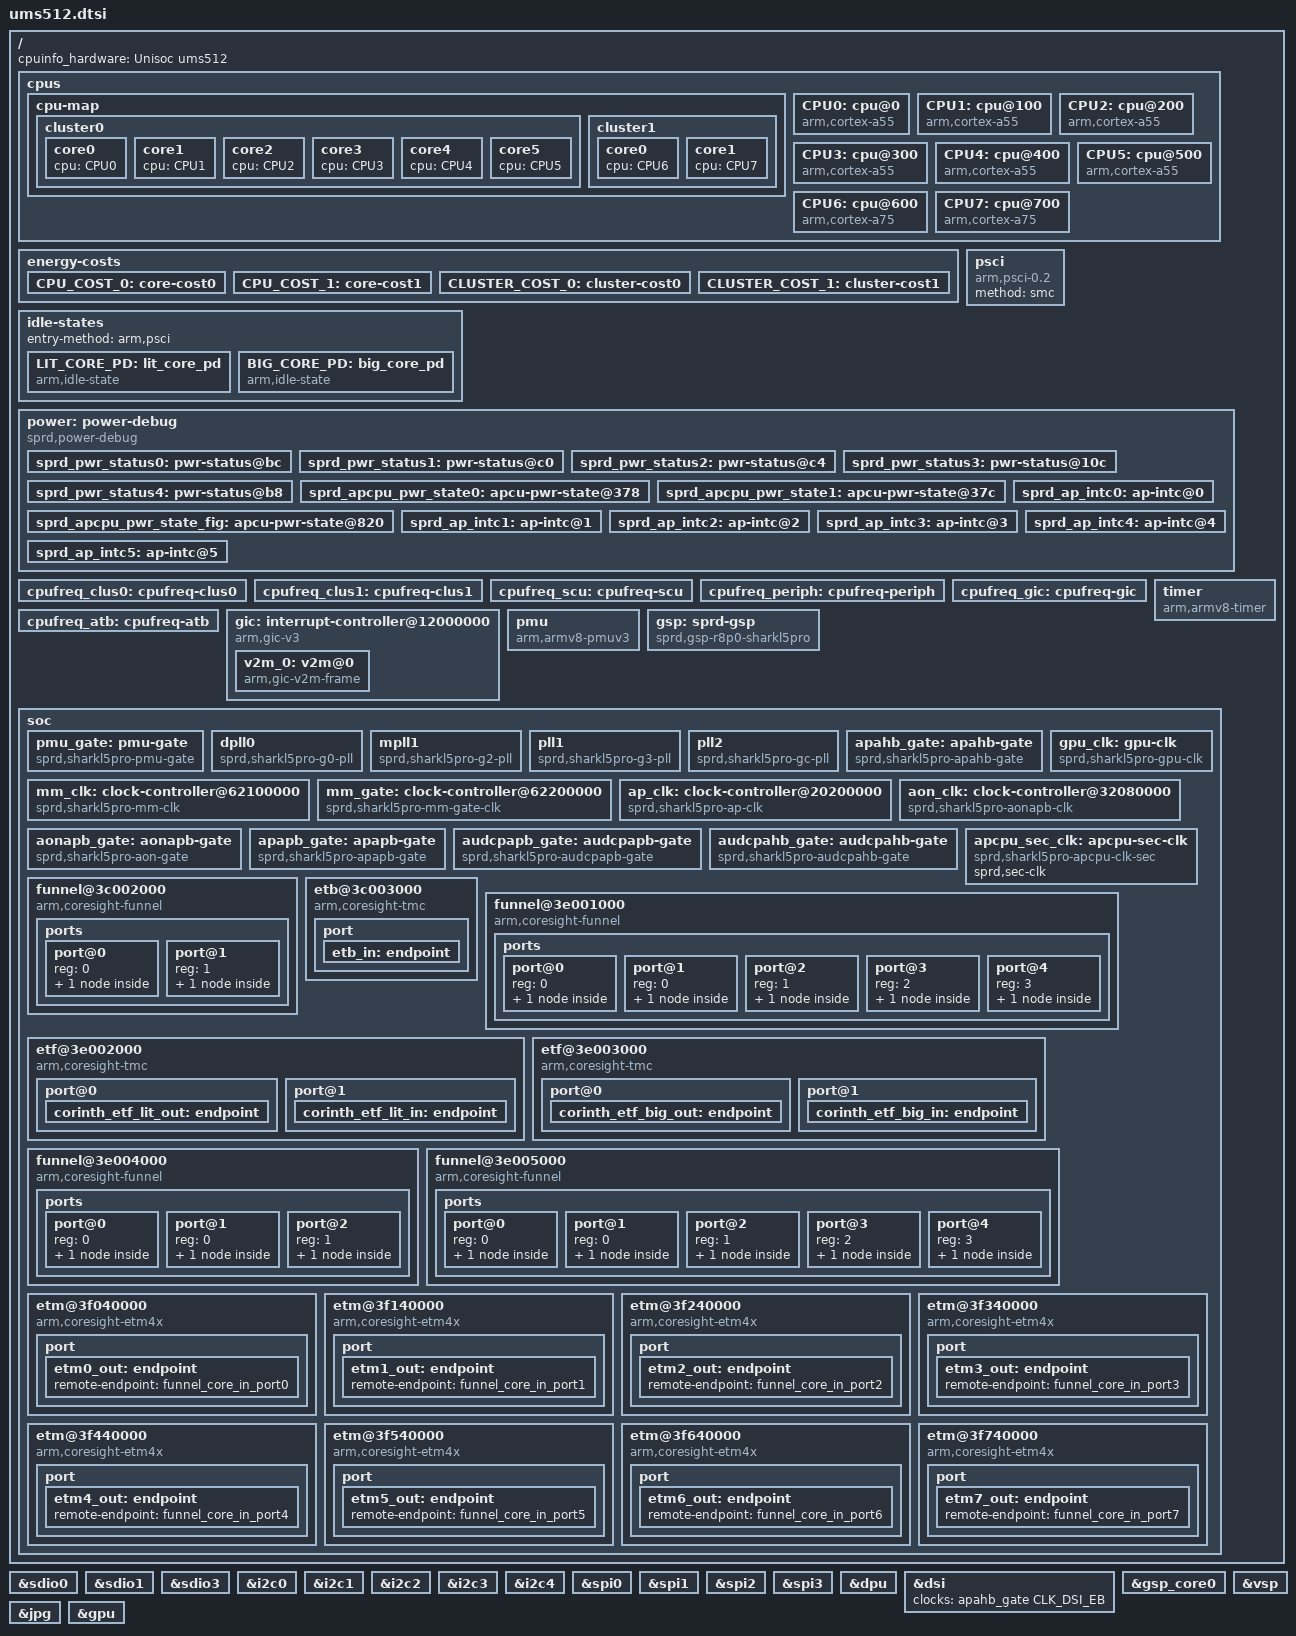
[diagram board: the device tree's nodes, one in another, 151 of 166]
// SPDX-License-Identifier: (GPL-2.0+ OR MIT)
/*
 * Unisoc Sharkl5Pro platform DTS file
 *
 * Copyright (C) 2018, Unisoc Communications Inc.
 */

#include "sharkl5Pro.dtsi"
#include "ums512-qos.dtsi"

/ {
	cpuinfo_hardware = "Unisoc ums512";

	cpus {
		#address-cells = <2>;
		#size-cells = <0>;

		cpu-map {
			cluster0 {
				core0 {
					cpu = <&CPU0>;
				};
				core1 {
					cpu = <&CPU1>;
				};
				core2 {
					cpu = <&CPU2>;
				};
				core3 {
					cpu = <&CPU3>;
				};
				core4 {
					cpu = <&CPU4>;
				};
				core5 {
					cpu = <&CPU5>;
				};
			};
			cluster1 {
				core0 {
					cpu = <&CPU6>;
				};
				core1 {
					cpu = <&CPU7>;
				};
			};
		};

		CPU0: cpu@0 {
			device_type = "cpu";
			compatible = "arm,cortex-a55","arm,armv8";
			reg = <0x0 0x0>;
			enable-method = "psci";
			cpu-idle-states = <&LIT_CORE_PD>;
			cpufreq-data-v1 = <&cpufreq_clus0>;
			sched-energy-costs = <&CPU_COST_0 &CLUSTER_COST_0>;
			capacity-dmips-mhz = <544>;
			sugov_slack_timer;
		};
		CPU1: cpu@100 {
			device_type = "cpu";
			compatible = "arm,cortex-a55","arm,armv8";
			reg = <0x0 0x100>;
			enable-method = "psci";
			cpu-idle-states = <&LIT_CORE_PD>;
			sched-energy-costs = <&CPU_COST_0 &CLUSTER_COST_0>;
			capacity-dmips-mhz = <544>;
			cpufreq-data-v1 = <&cpufreq_clus0>;
		};
		CPU2: cpu@200 {
			device_type = "cpu";
			compatible = "arm,cortex-a55","arm,armv8";
			reg = <0x0 0x200>;
			enable-method = "psci";
			cpu-idle-states = <&LIT_CORE_PD>;
			sched-energy-costs = <&CPU_COST_0 &CLUSTER_COST_0>;
			capacity-dmips-mhz = <544>;
			cpufreq-data-v1 = <&cpufreq_clus0>;
		};
		CPU3: cpu@300 {
			device_type = "cpu";
			compatible = "arm,cortex-a55","arm,armv8";
			reg = <0x0 0x300>;
			enable-method = "psci";
			cpu-idle-states = <&LIT_CORE_PD>;
			sched-energy-costs = <&CPU_COST_0 &CLUSTER_COST_0>;
			capacity-dmips-mhz = <544>;
			cpufreq-data-v1 = <&cpufreq_clus0>;
		};
		CPU4: cpu@400 {
			device_type = "cpu";
			compatible = "arm,cortex-a55","arm,armv8";
			reg = <0x0 0x400>;
			enable-method = "psci";
			cpu-idle-states = <&LIT_CORE_PD>;
			sched-energy-costs = <&CPU_COST_0 &CLUSTER_COST_0>;
			capacity-dmips-mhz = <544>;
			cpufreq-data-v1 = <&cpufreq_clus0>;
		};
		CPU5: cpu@500 {
			device_type = "cpu";
			compatible = "arm,cortex-a55","arm,armv8";
			reg = <0x0 0x500>;
			enable-method = "psci";
			cpu-idle-states = <&LIT_CORE_PD>;
			sched-energy-costs = <&CPU_COST_0 &CLUSTER_COST_0>;
			capacity-dmips-mhz = <544>;
			cpufreq-data-v1 = <&cpufreq_clus0>;
		};
		CPU6: cpu@600 {
			device_type = "cpu";
			compatible = "arm,cortex-a75","arm,armv8";
			reg = <0x0 0x600>;
			enable-method = "psci";
			cpu-idle-states = <&BIG_CORE_PD>;
			sched-energy-costs = <&CPU_COST_1 &CLUSTER_COST_1>;
			capacity-dmips-mhz = <1024>;
			cpufreq-data-v1 = <&cpufreq_clus1>;
		};
		CPU7: cpu@700 {
			device_type = "cpu";
			compatible = "arm,cortex-a75","arm,armv8";
			reg = <0x0 0x700>;
			enable-method = "psci";
			cpu-idle-states = <&BIG_CORE_PD>;
			sched-energy-costs = <&CPU_COST_1 &CLUSTER_COST_1>;
			capacity-dmips-mhz = <1024>;
			cpufreq-data-v1 = <&cpufreq_clus1>;
		};
	};

	energy-costs {
		CPU_COST_0: core-cost0 {
			busy-cost-data = <
				164	30		//614MHz
				206	42		//768MHz
				257	56		//962MHz
				307	70		//1144MHz
				329	85		//1229MHz
				397	115		//1482MHz
				412	134		//1536MHz
				460	166		//1716MHz
				488	194		//1820MHz
			>;
			idle-cost-data = <
				6		/* ACTIVE-IDLE */
				6		/* WFI */
				0		/* CORE_PD */
			>;

			busy-cost-data-lp = <
				183	34		//614MHz
				229	54		//768MHz
				287	67		//962MHz
				342	78		//1144MHz
				367	84		//1229MHz
				443	127		//1482MHz
				459	132		//1536MHz
				513	182		//1716MHz
				544	193		//1820MHz
			>;
			idle-cost-data-lp = <
				5		/* ACTIVE-IDLE */
				5		/* WFI */
				0		/* CORE_PD */
			>;

			busy-cost-data-hp = <
				167	34		//614MHz
				209	54		//768MHz
				261	67		//962MHz
				311	78		//1144MHz
				334	84		//1229MHz
				403	127		//1482MHz
				417	132		//1536MHz
				466	182		//1716MHz
				495	193		//1820MHz
				544	224		//2002MHz
			>;
			idle-cost-data-hp = <
				6		/* ACTIVE-IDLE */
				6		/* WFI */
				0		/* CORE_PD */
			>;
		};
		CPU_COST_1: core-cost1 {
			busy-cost-data = <
				621	331		//1229MHz
				748	454		//1482MHz
				776	540		//1536MHz
				880	683		//1742MHz
				945	820		//1872MHz
				1024	984		//2028MHz
			>;
			idle-cost-data = <
				37		/* ACTIVE-IDLE */
				37		/* WFI */
				0		/* CORE_PD */
			>;

			busy-cost-data-lp = <
				691	360		//1229MHz
				834	491		//1482MHz
				864	644		//1536MHz
				980	902		//1742MHz
				1024	943		//1820MHz
			>;
			idle-cost-data-lp = <
				21		/* ACTIVE-IDLE */
				21		/* WFI */
				0		/* CORE_PD */
			>;

			busy-cost-data-hp = <
				629	360		//1229MHz
				758	491		//1482MHz
				786	644		//1536MHz
				891	902		//1742MHz
				931	943		//1820MHz
				1024	1036		//2002MHz
			>;
			idle-cost-data-hp = <
				21		/* ACTIVE-IDLE */
				21		/* WFI */
				0		/* CORE_PD */
			>;
		};
		CLUSTER_COST_0: cluster-cost0 {
			busy-cost-data = <
				164	1		//614MHz
				206	2		//768MHz
				257	3		//962MHz
				307	4		//1144MHz
				329	5		//1229MHz
				397	6		//1482MHz
				412	7		//1536MHz
				460	8		//1716MHz
				488	9		//1820MHz
			>;
			idle-cost-data = <
				0		/* ACTIVE-IDLE */
				0		/* WFI */
				0		/* CORE_PD */
			>;

			busy-cost-data-lp = <
				183	1		//614MHz
				229	2		//768MHz
				287	3	        //962MHz
				342	4		//1144MHz
				367	5		//1229MHz
				443	6		//1482MHz
				459	7		//1536MHz
				513	8		//1716MHz
				544	9		//1820MHz
			>;
			idle-cost-data-lp = <
				0		/* ACTIVE-IDLE */
				0		/* WFI */
				0		/* CORE_PD */
			>;

			busy-cost-data-hp = <
				167	1		//614MHz
				209	2		//768MHz
				261	3		//962MHz
				311	4		//1144MHz
				334	5		//1229MHz
				403	6		//1482MHz
				417	7		//1536MHz
				466	8		//1716MHz
				495	9		//1820MHz
				544	10		//2002MHz
			>;
			idle-cost-data-hp = <
				0		/* ACTIVE-IDLE */
				0		/* WFI */
				0		/* CORE_PD */
			>;
		};
		CLUSTER_COST_1: cluster-cost1 {
			busy-cost-data = <
				621	13		//1229MHz
				748	17		//1482MHz
				776	21		//1536MHz
				880	25		//1742MHz
				945	30		//1872MHz
				1024	35		//2028MHz
			>;
			idle-cost-data = <
				23		/* ACTIVE-IDLE */
				23		/* WFI */
				23		/* CORE_PD */
			>;

			busy-cost-data-lp = <
				691	10		//1229MHz
				834	22		//1482MHz
				864	32		//1536MHz
				980	44		//1742MHz
				1024	46		//1820MHz
			>;
			idle-cost-data-lp = <
				5		/* ACTIVE-IDLE */
				5		/* WFI */
				5		/* CORE_PD */
			>;

			busy-cost-data-hp = <
				629	10		//1229MHz
				758	22		//1482MHz
				786	32		//1536MHz
				891	40		//1742MHz
				931	44		//1820MHz
				1024	46		//2002MHz
			>;
			idle-cost-data-hp = <
				5		/* ACTIVE-IDLE */
				5		/* WFI */
				5		/* CORE_PD */
			>;
		};
	};

	psci {
		compatible = "arm,psci-0.2";
		method = "smc";
	};

	idle-states {
		entry-method = "arm,psci";
		LIT_CORE_PD: lit_core_pd {
			compatible = "arm,idle-state";
			entry-latency-us = <1000>;
			exit-latency-us = <500>;
			min-residency-us = <2500>;
			local-timer-stop;
			arm,psci-suspend-param = <0x00010000>;
		};

		BIG_CORE_PD: big_core_pd {
			compatible = "arm,idle-state";
			entry-latency-us = <4000>;
			exit-latency-us = <4000>;
			min-residency-us = <10000>;
			local-timer-stop;
			arm,psci-suspend-param = <0x00010000>;
		};
	};

	power: power-debug {
		compatible = "sprd,power-debug";
		#address-cells = <1>;
		#size-cells = <0>;

		sprd,sys-ap-ahb = <&ap_ahb_regs>;

		/* <reg-addr mask expect-value> */
		sprd,ap-ahb-reg-tbl =
			<REG_AP_AHB_RF_AHB_EB
			( MASK_AP_AHB_RF_BUSMON_CLOCK_EB
			| MASK_AP_AHB_RF_CKG_EB
			| MASK_AP_AHB_RF_IPI_EB
			| MASK_AP_AHB_RF_DMA_EB
			| MASK_AP_AHB_RF_DMA_ENABLE
			| MASK_AP_AHB_RF_VDMA_EB
			| MASK_AP_AHB_RF_VSP_EB
			| MASK_AP_AHB_RF_DISPC_EB
			| MASK_AP_AHB_RF_DSI_EB )
			MASK_AP_AHB_RF_CKG_EB>,
			<REG_AP_AHB_RF_AP_SYS_FORCE_SLEEP_CFG
			( MASK_AP_AHB_RF_AXI_LP_CTRL_DISABLE
			| MASK_AP_AHB_RF_PERI_FORCE_OFF )
			( MASK_AP_AHB_RF_AXI_LP_CTRL_DISABLE
			| MASK_AP_AHB_RF_PERI_FORCE_OFF)>,
			<REG_AP_AHB_RF_M0_LPC MASK_AP_AHB_RF_MAIN_M0_LP_EB MASK_AP_AHB_RF_MAIN_M0_LP_EB>,
			<REG_AP_AHB_RF_M1_LPC MASK_AP_AHB_RF_MAIN_M1_LP_EB MASK_AP_AHB_RF_MAIN_M1_LP_EB>,
			<REG_AP_AHB_RF_M2_LPC MASK_AP_AHB_RF_MAIN_M2_LP_EB MASK_AP_AHB_RF_MAIN_M2_LP_EB>,
			<REG_AP_AHB_RF_M3_LPC MASK_AP_AHB_RF_MAIN_M3_LP_EB MASK_AP_AHB_RF_MAIN_M3_LP_EB>,
			<REG_AP_AHB_RF_M4_LPC MASK_AP_AHB_RF_MAIN_M4_LP_EB MASK_AP_AHB_RF_MAIN_M4_LP_EB>,
			<REG_AP_AHB_RF_M5_LPC MASK_AP_AHB_RF_MAIN_M5_LP_EB MASK_AP_AHB_RF_MAIN_M5_LP_EB>,
			<REG_AP_AHB_RF_M6_LPC MASK_AP_AHB_RF_MAIN_M6_LP_EB MASK_AP_AHB_RF_MAIN_M6_LP_EB>,
			<REG_AP_AHB_RF_M7_LPC MASK_AP_AHB_RF_MAIN_M7_LP_EB MASK_AP_AHB_RF_MAIN_M7_LP_EB>,
			<REG_AP_AHB_RF_S0_LPC MASK_AP_AHB_RF_MAIN_S0_LP_EB MASK_AP_AHB_RF_MAIN_S0_LP_EB>,
			<REG_AP_AHB_RF_S1_LPC MASK_AP_AHB_RF_MAIN_S1_LP_EB MASK_AP_AHB_RF_MAIN_S1_LP_EB>,
			<REG_AP_AHB_RF_S2_LPC MASK_AP_AHB_RF_MAIN_S2_LP_EB MASK_AP_AHB_RF_MAIN_S2_LP_EB>,
			<REG_AP_AHB_RF_S3_LPC MASK_AP_AHB_RF_MAIN_S3_LP_EB MASK_AP_AHB_RF_MAIN_S3_LP_EB>,
			<REG_AP_AHB_RF_S4_LPC MASK_AP_AHB_RF_MAIN_S4_LP_EB MASK_AP_AHB_RF_MAIN_S4_LP_EB>,
			<REG_AP_AHB_RF_S5_LPC MASK_AP_AHB_RF_MAIN_S5_LP_EB MASK_AP_AHB_RF_MAIN_S5_LP_EB>,
			<REG_AP_AHB_RF_S6_LPC MASK_AP_AHB_RF_MAIN_S6_LP_EB MASK_AP_AHB_RF_MAIN_S6_LP_EB>,
			<REG_AP_AHB_RF_S7_LPC MASK_AP_AHB_RF_MAIN_S7_LP_EB MASK_AP_AHB_RF_MAIN_S7_LP_EB>,
			<REG_AP_AHB_RF_MERGE_M1_LPC MASK_AP_AHB_RF_MERGE_M1_LP_EB MASK_AP_AHB_RF_MERGE_M1_LP_EB>,
			<REG_AP_AHB_RF_MERGE_S0_LPC MASK_AP_AHB_RF_MERGE_S0_LP_EB MASK_AP_AHB_RF_MERGE_S0_LP_EB>,
			<REG_AP_AHB_RF_DISP_ASYNC_BRG MASK_AP_AHB_RF_DISP_ASYNC_BRG_LP_EB MASK_AP_AHB_RF_DISP_ASYNC_BRG_LP_EB>,
			<REG_AP_AHB_RF_AP_ASYNC_BRG MASK_AP_AHB_RF_AP_ASYNC_BRG_LP_EB MASK_AP_AHB_RF_AP_ASYNC_BRG_LP_EB>;

		sprd,sys-ap-apb = <&ap_apb_regs>;

		sprd,ap-apb-reg-tbl =
			<REG_AP_APB_RF_APB_EB
			( MASK_AP_APB_RF_CE_PUB_EB
			| MASK_AP_APB_RF_CE_SEC_EB
			| MASK_AP_APB_RF_EMMC_EB
			| MASK_AP_APB_RF_SDIO2_EB
			| MASK_AP_APB_RF_SDIO1_EB
			| MASK_AP_APB_RF_SDIO0_EB
			| MASK_AP_APB_RF_UART2_EB
			| MASK_AP_APB_RF_UART1_EB
			| MASK_AP_APB_RF_UART0_EB
			| MASK_AP_APB_RF_I2C4_EB
			| MASK_AP_APB_RF_I2C3_EB
			| MASK_AP_APB_RF_I2C2_EB
			| MASK_AP_APB_RF_I2C1_EB
			| MASK_AP_APB_RF_I2C0_EB
			| MASK_AP_APB_RF_SPI3_EB
			| MASK_AP_APB_RF_SPI2_EB
			| MASK_AP_APB_RF_SPI1_EB
			| MASK_AP_APB_RF_SPI0_EB
			| MASK_AP_APB_RF_IIS2_EB
			| MASK_AP_APB_RF_IIS1_EB
			| MASK_AP_APB_RF_IIS0_EB
			| MASK_AP_APB_RF_SIM0_EB )
			0x00000000>,
			<REG_AP_APB_RF_APB_MISC_CTRL
			( MASK_AP_APB_RF_I2C4_SEC_EB
			| MASK_AP_APB_RF_I2C3_SEC_EB
			| MASK_AP_APB_RF_I2C2_SEC_EB
			| MASK_AP_APB_RF_I2C1_SEC_EB
			| MASK_AP_APB_RF_I2C0_SEC_EB
			| MASK_AP_APB_RF_SPI3_SEC_EB
			| MASK_AP_APB_RF_SPI2_SEC_EB
			| MASK_AP_APB_RF_SPI1_SEC_EB
			| MASK_AP_APB_RF_SPI0_SEC_EB )
			0x00000000>;

		sprd,sys-pmu-apb = <&pmu_apb_regs>;

		sprd,pmu-apb-reg-tbl =
			<REG_PMU_APB_RF_PUB_SYS_AUTO_LIGHT_SLEEP_ENABLE MASK_PMU_APB_RF_PUB_SYS_AUTO_LIGHT_SLEEP_ENABLE 0x00000000>,
			<REG_PMU_APB_RF_SLEEP_CTRL
			( MASK_PMU_APB_RF_PUB_SYS_FORCE_LIGHT_SLEEP
			| MASK_PMU_APB_RF_PUB_SYS_FORCE_DEEP_SLEEP
			| MASK_PMU_APB_RF_PUB_SYS_AUTO_DEEP_SLEEP_ENABLE
			| MASK_PMU_APB_RF_AON_DMA_FORCE_LIGHT_SLEEP
			| MASK_PMU_APB_RF_PUBCP_FORCE_LIGHT_SLEEP
			| MASK_PMU_APB_RF_WTLCP_FORCE_LIGHT_SLEEP
			| MASK_PMU_APB_RF_AUDCP_FORCE_LIGHT_SLEEP
			| MASK_PMU_APB_RF_AP_FORCE_LIGHT_SLEEP
			| MASK_PMU_APB_RF_AON_SYS_FORCE_LIGHT_SLEEP
			| MASK_PMU_APB_RF_AUDCP_FORCE_PUB_DEEP_SLEEP
			| MASK_PMU_APB_RF_SP_SYS_FORCE_DEEP_SLEEP
			| MASK_PMU_APB_RF_AUDCP_FORCE_DEEP_SLEEP
			| MASK_PMU_APB_RF_PUBCP_FORCE_DEEP_SLEEP
			| MASK_PMU_APB_RF_WTLCP_FORCE_DEEP_SLEEP
			| MASK_PMU_APB_RF_AP_FORCE_DEEP_SLEEP
			| MASK_PMU_APB_RF_CDMA_FORCE_DEEP_SLEEP
			| MASK_PMU_APB_RF_AUDCP_FORCE_SYSTEM_SLEEP
			| MASK_PMU_APB_RF_GPU_TOP_FORCE_SYSTEM_SLEEP
			| MASK_PMU_APB_RF_PUBCP_FORCE_SYSTEM_SLEEP
			| MASK_PMU_APB_RF_WTLCP_FORCE_SYSTEM_SLEEP
			| MASK_PMU_APB_RF_AP_FORCE_SYSTEM_SLEEP
			| MASK_PMU_APB_RF_APCPU_FORCE_SYSTEM_SLEEP
			| MASK_PMU_APB_RF_AP_ALL_FORCE_SYSTEM_SLEEP
			| MASK_PMU_APB_RF_SP_SYS_DEEP_SLEEP
			| MASK_PMU_APB_RF_AUDCP_DEEP_SLEEP
			| MASK_PMU_APB_RF_PUB_SYS_DEEP_SLEEP
			| MASK_PMU_APB_RF_CDMA_DEEP_SLEEP
			| MASK_PMU_APB_RF_PUBCP_DEEP_SLEEP
			| MASK_PMU_APB_RF_WTLCP_DEEP_SLEEP
			| MASK_PMU_APB_RF_AP_DEEP_SLEEP )
			0x00000000>,
			<REG_PMU_APB_RF_SLEEP_STATUS
			( MASK_PMU_APB_RF_CDMA_AUTO_SLP_STATUS
			| MASK_PMU_APB_RF_SP_SYS_SLP_STATUS
			| MASK_PMU_APB_RF_CDMA_SLP_STATUS
			| MASK_PMU_APB_RF_AUDCP_SLP_STATUS
			| MASK_PMU_APB_RF_PUBCP_SLP_STATUS
			| MASK_PMU_APB_RF_WTLCP_SLP_STATUS
			| MASK_PMU_APB_RF_AP_SLP_STATUS )
			0x00000000>,
			<REG_PMU_APB_RF_LIGHT_SLEEP_ENABLE
			( MASK_PMU_APB_RF_PUB_SYS_SMART_LSLP_ENA
			| MASK_PMU_APB_RF_MM_LSLP_ENA
			| MASK_PMU_APB_RF_GPU_LSLP_ENA
			| MASK_PMU_APB_RF_AUDCP_SYS_LSLP_ENA
			| MASK_PMU_APB_RF_AON_DMA_LSLP_ENA
			| MASK_PMU_APB_RF_WTLCP_LSLP_ENA
			| MASK_PMU_APB_RF_PUBCP_LSLP_ENA
			| MASK_PMU_APB_RF_AP_LSLP_ENA )
			0x00000000>,
			<REG_PMU_APB_RF_AXI_LP_CTRL_DISABLE MASK_PMU_APB_RF_AXI_LP_CTRL_DISABLE MASK_PMU_APB_RF_AXI_LP_CTRL_DISABLE>;

		sprd,sys-aon-apb = <&aon_apb_regs>;

		sprd,aon-apb-reg-tbl =
			<REG_AON_APB_RF_APB_EB0
			( MASK_AON_APB_RF_PROBE_EB
			| MASK_AON_APB_RF_AUX1_EB )
			0x00000000>,
			<REG_AON_APB_RF_APCPU_DEBUG_PWR_LP_CTRL MASK_AON_APB_RF_APCPU_LP_EB_DEBUG_PWR 0x00000000>,
			<REG_AON_APB_RF_APCPU_CLUSTER_ATB_LPC_CTRL MASK_AON_APB_RF_APCPU_CLUSTER_ATB_LP_EB 0x00000000>,
			<REG_AON_APB_RF_APCPU_CLUSTER_APB_LPC_CTRL MASK_AON_APB_RF_APCPU_CLUSTER_APB_LP_EB 0x00000000>,
			<REG_AON_APB_RF_APCPU_CLUSTER_GIC_LPC_CTRL MASK_AON_APB_RF_APCPU_CLUSTER_GIC_LP_EB 0x00000000>,
			<REG_AON_APB_RF_APCPU_GIC600_GIC_LPC_CTRL MASK_AON_APB_RF_APCPU_GIC600_GIC_LP_EB 0x00000000>,
			<REG_AON_APB_RF_APCPU_DBG_BLK_LPC_CTRL MASK_AON_APB_RF_APCPU_DBG_BLK_LP_EB 0x00000000>,
			<REG_AON_APB_RF_APCPU_TOP_MTX_M0_LPC_CTRL
			( MASK_AON_APB_RF_APCPU_TOP_MTX_MIAN_LP_EB
			| MASK_AON_APB_RF_APCPU_TOP_MTX_S3_LP_EB
			| MASK_AON_APB_RF_APCPU_TOP_MTX_S1_LP_EB
			| MASK_AON_APB_RF_APCPU_TOP_MTX_S0_LP_EB
			| MASK_AON_APB_RF_APCPU_TOP_MTX_M3_LP_EB
			| MASK_AON_APB_RF_APCPU_TOP_MTX_M2_LP_EB
			| MASK_AON_APB_RF_APCPU_TOP_MTX_M0_LP_EB )
			0x00000000>,
			<REG_AON_APB_RF_APCPU_CLUSTER_SCU_LPC_CTRL MASK_AON_APB_RF_APCPU_CLUSTER_SCU_LP_EB 0x00000000>,
			<REG_AON_APB_RF_APCPU_DDR_AB_LPC_CTRL MASK_AON_APB_RF_APCPU_DDR_AB_LP_EB 0x00000000>;

		sprd,sys-ap-intc = <&ap_intc0_regs &ap_intc1_regs
				&ap_intc2_regs &ap_intc3_regs
				&ap_intc4_regs &ap_intc5_regs>;

		sprd,ap-intc = <&sprd_ap_intc0 &sprd_ap_intc1 &sprd_ap_intc2
				&sprd_ap_intc3 &sprd_ap_intc4 &sprd_ap_intc5>;

		sprd,pdm-name = <&sprd_pwr_status0 &sprd_pwr_status1
				&sprd_pwr_status2 &sprd_pwr_status3
				&sprd_pwr_status4 &sprd_apcpu_pwr_state0
				&sprd_apcpu_pwr_state1 &sprd_apcpu_pwr_state_fig>;

		sprd_pwr_status0: pwr-status@bc {
			reg = <REG_PMU_APB_RF_PWR_STATUS0_DBG>;
			sprd,bit-width = <8>;
			sprd,bit-index = <0 8 16 24>;
			sprd,pdm-names = "PD_AP_SYS", "PD_AP_VSP",
				"PD_CDMA_SYS", "PD_AP_VDSP";
		};
		sprd_pwr_status1: pwr-status@c0 {
			reg = <REG_PMU_APB_RF_PWR_STATUS1_DBG>;
			sprd,bit-width = <8>;
			sprd,bit-index = <0 8 16 24>;
			sprd,pdm-names = "PD_WTLCP_HU3GE_A", "PD_WTLCP_TGDSP",
				"PD_WTLCP_LDSP", "PD_WTLCP_HU3GE_B";
		};
		sprd_pwr_status2: pwr-status@c4 {
			reg = <REG_PMU_APB_RF_PWR_STATUS2_DBG>;
			sprd,bit-width = <8>;
			sprd,bit-index = <0 8 16 24>;
			sprd,pdm-names = "PD_WTLCP_SYS", "PD_PUBCP_SYS",
				"PD_WTLCP_LTE_PROC", "PD_WTLCP_TD_PROC";
		};
		sprd_pwr_status3: pwr-status@10c{
			reg = <REG_PMU_APB_RF_PWR_STATUS3_DBG>;
			sprd,bit-width = <8>;
			sprd,bit-index = <0 8 16 24>;
			sprd,pdm-names = "PD_AUDCP_AUDDSP", "PD_GPU_TOP",
				"PD_MM_TOP", "null";
		};
		sprd_pwr_status4: pwr-status@b8 {
			reg = <REG_PMU_APB_RF_PWR_STATUS4_DBG>;
			sprd,bit-width = <8>;
			sprd,bit-index = <0 8 16 24>;
			sprd,pdm-names = "PD_WTLCP_LTE_DPFEC", "PD_WTLCP_LTE_CE",
				"PD_PUB_SYS", "PD_AUDCP_SYS";
		};
		sprd_apcpu_pwr_state0: apcu-pwr-state@378 {
			reg = <REG_PMU_APB_RF_APCU_PWR_STATE0>;
			sprd,bit-width = <8>;
			sprd,bit-index = <0 8 16 24>;
			sprd,pdm-names = "PD_APCPU_TOP", "PD_APCPU_C0",
				"PD_APCPU_C1", "PD_APCPU_C2";
		};
		sprd_apcpu_pwr_state1: apcu-pwr-state@37c {
			reg = <REG_PMU_APB_RF_APCU_PWR_STATE1>;
			sprd,bit-width = <8>;
			sprd,bit-index = <0 8 16 24>;
			sprd,pdm-names = "PD_APCPU_C7", "null", "null", "null";
		};
		sprd_apcpu_pwr_state_fig: apcu-pwr-state@820 {
			reg = <REG_PMU_APB_RF_APCU_PWR_STATE_FIG>;
			sprd,bit-width = <8>;
			sprd,bit-index = <0 8 16 24>;
			sprd,pdm-names = "PD_APCPU_C6", "PD_APCPU_C5", "PD_APCPU_C4", "PD_APCPU_C3";
		};

		sprd_ap_intc0: ap-intc@0 {
			reg = <0x0000>;
			sprd,int-names = "null", "null", "AP_UART0", "AP_UART1",
				"AP_UART2", "AP_SPI0",	"AP_SPI1", "AP_SPI2",
				"AP_SPI3", "AP_SIM", "AP_EMMC",	"AP_I2C0",
				"AP_I2C1", "AP_I2C2", "AP_I2C3", "AP_I2C4",
				"AP_IIS0", "AP_IIS1", "AP_IIS2", "AP_SDIO0",
				"AP_SDIO1", "AP_SDIO2", "CE_SEC", "CE_PUB",
				"AP_DMA", "DMA_SEC_AP", "GSP", "DISPC",
				"SLV_FW_AP_INTERRUPT", "DSI_PLL", "DSI0",
				"DSI1";
		};
		sprd_ap_intc1: ap-intc@1 {
			reg = <0x0000>;
			sprd,int-names = "null", "null", "VSP", "null",
				"null", "null", "null", "null",
				"FD_ARM_INT", "CPP_ARM_INT",
				"JPG_ARM_INT", "ISP_CH0", "ISP_CH1",
				"CSI0_CAL_FAILED", "CSI0_CAL_DONE",
				"CSI0_R2", "CSI0_R1", "CSI1_CAL_FAILED",
				"CSI1_CAL_DONE", "CSI1_R2", "CSI1_R1",
				"CSI2_CAL_FAILED", "CSI2_CAL_DONE",
				"CSI2_R2", "CSI2_R1", "DCAM0_ARM",
				"DCAM1_ARM", "DCAM2_ARM", "GPU", "GPIO",
				"THM0", "THM1";
		};
		sprd_ap_intc2: ap-intc@2 {
			reg = <0x0000>;
			sprd,int-names = "null", "null", "THM2", "KPD",
				"AON_I2C", "OTG", "ADI", "AON_TMR",
				"EIC", "AP_TMR0", "AP_TMR1", "AP_TMR2",
				"AP_TMR3", "AP_TMR4", "AP_SYST", "APCPU_WDG",
				"AP_WDG", "BUSMON_AON", "MBOX_SRC_AP",
				"MBOX_TAR_AP", "MBOX_TAR_SIPC_AP_NOWAKEUP",
				"PWR_UP_AP", "PWR_UP_PUB", "PWR_UP_ALL",
				"PWR_DOWN_ALL", "SEC_EIC", "SEC_EIC_NON_LAT",
				"SEC_WDG", "SEC_RTC", "SEC_TMR", "SEC_GPIO",
				"SLV_FW_AON";
		};
		sprd_ap_intc3: ap-intc@3 {
			reg = <0x0000>;
			sprd,int-names = "null", "null", "MEM_FW_AON", "AON_32K_DET",
				"SCC", "IIS", "APB_BUSMON", "EXT_RSTB_APCPU",
				"AON_SYST", "MEM_FW_PUB", "PUB_HDW_DFS_EXIT",
				"PUB_DFS_ERROR", "PUB_DFS_COMPLETE", "PUB_PTM",
				"DFI_BUS_MONITOR_PUB", "REG_PUB_DMC_MPU_VIO",
				"NPMUIRQ0", "NPMUIRQ1", "NPMUIRQ2", "NPMUIRQ3",
				"null", "null", "null", "null",
				"NCTIIRQ0", "NCTIIRQ1", "NCTIIRQ2", "NCTIIRQ3",
				"null", "null", "null", "null";
		};
		sprd_ap_intc4: ap-intc@4 {
			reg = <0x0000>;
			sprd,int-names = "null", "null", "NERRIRQ1",
				"NERRIRQ2", "NERRIRQ3", "NERRIRQ4",
				"NERRIRQ5", "NERRIRQ6",	"NERRIRQ7",
				"NERRIRQ8", "NFAULTIRQ1", "NFAULTIRQ2",
				"NFAULTIRQ3", "NFAULTIRQ4", "NFAULTIRQ5",
				"NFAULTIRQ6", "NFAULTIRQ7", "NFAULTIRQ8",
				"NCNTPNSIRQ0", "NCNTPNSIRQ1",
				"NCNTPNSIRQ2", "NCNTPNSIRQ3", "null", "null",
				"null", "null", "NCNTPSIRQ0", "NCNTPSIRQ1",
				"NCNTPSIRQ2", "NCNTPSIRQ3", "null", "null";
		};
		sprd_ap_intc5: ap-intc@5 {
			reg = <0x0000>;
			sprd,int-names = "null", "null", "null", "null",
				"NERRIRQ0", "NFAULTIRQ0", "APCPU_PMU",
				"APCPU_ERR", "APCPU_FAULTY", "null", "null",
				"APCPU_MODE_ST", "NCLUSTERPMUIRQ", "ANA",
				"WTLCP_TG_WDG_RST", "WTLCP_LTE_WDG_RST",
				"MDAR", "AUDCP_CHN_START_CHN0",
				"AUDCP_CHN_START_CHN1", "AUDCP_CHN_START_CHN2",
				"AUDCP_CHN_START_CHN3", "AUDCP_DMA",
				"AUDCP_MCDT", "AUDCP_VBC_AUDRCD",
				"AUDCP_VBC_AUDPLY", "AUDCP_WDG_RST",
				"ACC_PROT_PMU", "ACC_PROT_AON_APB_REG",
				"EIC_NON_LAT", "PUB_DFS_GIVEUP",
				"PUB_DFS_DENY", "PUB_DFS_VOTE_DONE";
		};
	};

	cpufreq_clus0: cpufreq-clus0 {
		cpufreq-cluster-id = <0>;
		cpufreq-sub-clusters =  <&cpufreq_scu>,
				<&cpufreq_periph>,
				<&cpufreq_gic>;
		clock-latency = <50000>;
		voltage-tolerance = <6413>;
		sprd,multi-version;
		operating-points = <
		/* kHZ   uV */
		1820000 1000000
		1716000 1000000
		1536000 900000
		1482000 900000
		1228800 800000
		1144000 800000
		962000  800000
		768000  800000
		614400  750000
	>;
	};

	cpufreq_clus1: cpufreq-clus1 {
		cpufreq-cluster-id = <1>;
		cpufreq-sub-clusters =  <&cpufreq_scu>,
				<&cpufreq_periph>,
				<&cpufreq_gic>;
		clock-latency = <50000>;
		voltage-tolerance = <6413>;
		sprd,multi-version;
		operating-points = <
		/* kHZ   uV */
		2002000 1000000
		1872000 1000000
		1742000 1000000
		1536000	 900000
		1482000	 800000
		1228800	 750000
	>;
	};

	cpufreq_scu: cpufreq-scu {
		cpufreq-cluster-id = <2>;
		clock-latency = <50000>;
		voltage-tolerance = <0>;
		sprd,multi-version;
		operating-points = <
		/* kHz   uV */
		1404000 1000000
		1326000 1000000
		1222000 900000
		1118000 900000
		1014000 800000
		962000  800000
		768000  800000
		650000  800000
		546000  750000
	>;
	};

	cpufreq_periph: cpufreq-periph {
		cpufreq-cluster-id = <3>;
		clock-latency = <50000>;
		voltage-tolerance = <0>;
		sprd,multi-version;
		operating-points = <
		/* kHZ  uV */
		768000 1000000
		512000 800000
		384000 800000
		256000 800000
		153600 750000
	>;
	};

	cpufreq_gic: cpufreq-gic {
		cpufreq-cluster-id = <4>;
		clock-latency = <50000>;
		voltage-tolerance = <0>;
		sprd,multi-version;
		operating-points = <
		/* kHZ  uV */
		512000 800000
		384000 800000
		256000 800000
		192000 800000
		153600 750000
	>;
	};

	cpufreq_atb: cpufreq-atb {
		cpufreq-cluster-id = <5>;
		sprd,multi-version;
		operating-points = <
		/* kHZ  uV */
		768000 1000000
		512000 800000
		384000 800000
		256000 750000
		153600 750000
	>;
	};

	gic: interrupt-controller@12000000 {
		compatible = "arm,gic-v3";
		#interrupt-cells = <3>;
		#address-cells = <2>;
		#size-cells = <2>;
		ranges;
		redistributor-stride = <0x0 0x20000>;	/* 128KB stride */
		#redistributor-regions = <1>;
		interrupt-controller;
		reg = <0x0 0x12000000 0 0x20000>,	/* GICD */
			<0x0 0x12040000 0 0x100000>;	/* GICR */
		interrupts = <1 9 4>;
		v2m_0: v2m@0 {
			compatible = "arm,gic-v2m-frame";
			msi-controller;
			reg = <0 0 0 0x1000>;
		};
	};

	timer {
		compatible = "arm,armv8-timer";
		interrupts = <GIC_PPI 13 IRQ_TYPE_LEVEL_HIGH>, /* Physical Secure PPI */
			<GIC_PPI 14 IRQ_TYPE_LEVEL_HIGH>, /* Physical Non-Secure PPI */
			<GIC_PPI 11 IRQ_TYPE_LEVEL_HIGH>, /* Virtual PPI */
			<GIC_PPI 10 IRQ_TYPE_LEVEL_HIGH>; /* Hipervisor PPI */
		arm,no-tick-in-suspend;
	};
	pmu {
		compatible = "arm,armv8-pmuv3";
		interrupts = <GIC_SPI 112 IRQ_TYPE_LEVEL_HIGH>,
			<GIC_SPI 113 IRQ_TYPE_LEVEL_HIGH>,
			<GIC_SPI 114 IRQ_TYPE_LEVEL_HIGH>,
			<GIC_SPI 115 IRQ_TYPE_LEVEL_HIGH>,
			<GIC_SPI 116 IRQ_TYPE_LEVEL_HIGH>,
			<GIC_SPI 117 IRQ_TYPE_LEVEL_HIGH>,
			<GIC_SPI 118 IRQ_TYPE_LEVEL_HIGH>,
			<GIC_SPI 119 IRQ_TYPE_LEVEL_HIGH>;
	};

	 gsp: sprd-gsp {
		compatible = "sprd,gsp-r8p0-sharkl5pro";
		name = "sprd-gsp";
		core-cnt = <1>;
		io-cnt = <7>;
		cores = <&gsp_core0>;
	};

	soc {
		pmu_gate: pmu-gate {
			compatible = "sprd,sharkl5pro-pmu-gate";
			sprd,syscon = <&pmu_apb_regs>; /* 0x327e0000 */
			clocks = <&ext_26m>;
			#clock-cells = <1>;
		};

		dpll0: dpll0 {
			compatible = "sprd,sharkl5pro-g0-pll";
			sprd,syscon = <&anlg_phy_g0_regs>; /* 0x32390000 */
			clocks = <&pmu_gate CLK_DPLL0_GATE>;
			#clock-cells = <1>;
		};

		mpll1: mpll1 {
			compatible = "sprd,sharkl5pro-g2-pll";
			sprd,syscon = <&anlg_phy_g2_regs>; /* 0x323b0000 */
			clocks = <&pmu_gate CLK_MPLL1>;
			#clock-cells = <1>;
		};

		pll1: pll1 {
			compatible = "sprd,sharkl5pro-g3-pll";
			sprd,syscon = <&anlg_phy_g3_regs>; /* 0x323c0000 */
			clocks = <&pmu_gate 0>;
			#clock-cells = <1>;
		};

		pll2: pll2 {
			compatible = "sprd,sharkl5pro-gc-pll";
			sprd,syscon = <&anlg_phy_gc_regs>; /* 0x323e0000 */
			clocks = <&pmu_gate 0>;
			#clock-cells = <1>;
		};

		apahb_gate: apahb-gate {
			compatible = "sprd,sharkl5pro-apahb-gate";
			sprd,syscon = <&ap_ahb_regs>; /* 0x20100000 */
			clocks = <&ext_26m>;
			#clock-cells = <1>;
		};

		mm_clk: clock-controller@62100000 {
			compatible = "sprd,sharkl5pro-mm-clk";
			reg = <0 0x62100000 0 0x1000>;
			clocks = <&aonapb_gate CLK_MM_EB>;
			#clock-cells = <1>;
		};

		gpu_clk: gpu-clk {
			compatible = "sprd,sharkl5pro-gpu-clk";
			sprd,syscon = <&gpu_apb_regs>;
			syscons = <&aon_apb_regs REG_AON_APB_RF_APB_EB0 MASK_AON_APB_RF_GPU_EB>,
				  <&pmu_apb_regs REG_PMU_APB_RF_PD_GPU_TOP_CFG0 MASK_PMU_APB_RF_PD_GPU_TOP_FORCE_SHUTDOWN>;
			syscon-names = "enable", "power";
			clocks = <&aon_clk CLK_AP_MM>;
			#clock-cells = <1>;
		};

		mm_gate: clock-controller@62200000 {
			compatible = "sprd,sharkl5pro-mm-gate-clk";
			sprd,syscon = <&mm_ahb_regs>;
			syscons = <&aon_apb_regs REG_AON_APB_RF_APB_EB0 MASK_AON_APB_RF_MM_EB>,
				  <&pmu_apb_regs REG_PMU_APB_RF_PD_MM_TOP_CFG MASK_PMU_APB_RF_PD_MM_TOP_FORCE_SHUTDOWN>;
			syscon-names = "enable", "power";
			clocks = <&aonapb_gate CLK_MM_EB>;
			#clock-cells = <1>;
		};

		ap_clk: clock-controller@20200000 {
			compatible = "sprd,sharkl5pro-ap-clk";
			reg = <0 0x20200000 0 0x1000>;
			clocks = <&apapb_gate CLK_APB_REG_EB>;
			#clock-cells = <1>;
		};

		aon_clk: clock-controller@32080000 {
			compatible = "sprd,sharkl5pro-aonapb-clk";
			reg = <0 0x32080000 0 0x1000>;
			clocks = <&ext_26m>;
			#clock-cells = <1>;
		};

		aonapb_gate: aonapb-gate {
			compatible = "sprd,sharkl5pro-aon-gate";
			sprd,syscon = <&aon_apb_regs>; /* 0x327d0000 */
			clocks = <&ext_26m>;
			#clock-cells = <1>;
		};

		apapb_gate: apapb-gate {
			compatible = "sprd,sharkl5pro-apapb-gate";
			sprd,syscon = <&ap_apb_regs>; /* 0x71000000 */
			clocks = <&ext_26m>;
			#clock-cells = <1>;
		};

		audcpapb_gate: audcpapb-gate {
			compatible = "sprd,sharkl5pro-audcpapb-gate";
			sprd,syscon = <&audcp_apb_regs>; /* 0x3350d000 */
			clocks = <&ext_26m>;
			#clock-cells = <1>;
		};

		audcpahb_gate: audcpahb-gate {
			compatible = "sprd,sharkl5pro-audcpahb-gate";
			sprd,syscon = <&audcp_ahb_regs>; /* 0x335e0000 */
			clocks = <&ext_26m>;
			#clock-cells = <1>;
		};

		apcpu_sec_clk: apcpu-sec-clk {
			compatible = "sprd,sharkl5pro-apcpu-clk-sec";
			sprd,sec-clk;
			#clock-cells = <1>;
		};

		/*    etm */
		/* -> apcpu_funnel lit/big */
		/* -> apcpu_etf lit/big */
		/* -> funnel_to_soc */
		/* -> soc_funnel */
		/* -> soc_etf */

		/* soc_funnel */
		funnel@3c002000 {
			compatible = "arm,coresight-funnel", "arm,primecell";
			reg = <0 0x3c002000 0 0x1000>;
			clocks = <&ext_26m>;
			clock-names = "apb_pclk";
			ports {
				#address-cells = <1>;
				#size-cells = <0>;

				port@0 {
					reg = <0>;
					funnel_soc_out_port: endpoint {
						remote-endpoint = <&etb_in>;
					};
				};

				port@1 {
					reg = <1>;
					funnel_soc_in_port: endpoint {
						slave-mode;
						remote-endpoint = <&funnel_corinth_out_port>;
					};
				};
			};
		};

		/* soc_etf */
		etb@3c003000 {
			compatible = "arm,coresight-tmc", "arm,primecell";
			reg = <0 0x3c003000 0 0x1000>;
			clocks = <&ext_26m>;
			clock-names = "apb_pclk";
			port {
				etb_in: endpoint {
					slave-mode;
					remote-endpoint = <&funnel_soc_out_port>;
				};
			};
		};

		/* corinth funnel lit core3/4/5/7*/
		funnel@3e001000 {
			compatible = "arm,coresight-funnel", "arm,primecell";
			reg = <0 0x3e001000 0 0x1000>;
			clocks = <&ext_26m>;
			clock-names = "apb_pclk";

			ports {
				#address-cells = <1>;
				#size-cells = <0>;

				port@0 {
					reg = <0>;
					funnel_corinth_lit_out_port: endpoint {
						remote-endpoint = <&corinth_etf_lit_in>;
					};
				};

				port@1 {
					reg = <0>;
					funnel_core_in_port3: endpoint {
						slave-mode;
						remote-endpoint = <&etm3_out>;
					};
				};

				port@2 {
					reg = <1>;
					funnel_core_in_port4: endpoint {
						slave-mode;
						remote-endpoint = <&etm4_out>;
					};
				};

				port@3 {
					reg = <2>;
					funnel_core_in_port5: endpoint {
						slave-mode;
						remote-endpoint = <&etm5_out>;
					};
				};

				port@4 {
					reg = <3>;
					funnel_core_in_port7: endpoint {
						slave-mode;
						remote-endpoint = <&etm7_out>;
					};
				};
			};
		};

		/* corinth lit etf */
		etf@3e002000 {
			compatible = "arm,coresight-tmc", "arm,primecell";
			reg = <0 0x3e002000 0 0x1000>;
			clocks = <&ext_26m>;
			clock-names = "apb_pclk";

			port@0 {
				corinth_etf_lit_out: endpoint {
					remote-endpoint = <&funnel_corinth_from_lit_in_port>;
				};
			};

			port@1 {
				corinth_etf_lit_in: endpoint {
					slave-mode;
					remote-endpoint = <&funnel_corinth_lit_out_port>;
				};
			};
		};

		/* corinth big etf */
		etf@3e003000 {
			compatible = "arm,coresight-tmc", "arm,primecell";
			reg = <0 0x3e003000 0 0x1000>;
			clocks = <&ext_26m>;
			clock-names = "apb_pclk";

			port@0 {
				corinth_etf_big_out: endpoint {
					remote-endpoint = <&funnel_corinth_from_big_in_port>;
				};
			};

			port@1 {
				corinth_etf_big_in: endpoint {
					slave-mode;
					remote-endpoint = <&funnel_corinth_big_out_port>;
				};
			};
		};

		/* funnel to Soc */
		funnel@3e004000 {
			compatible = "arm,coresight-funnel", "arm,primecell";
			reg = <0 0x3e004000 0 0x1000>;
			clocks = <&ext_26m>;
			clock-names = "apb_pclk";
			ports {
				#address-cells = <1>;
				#size-cells = <0>;

				port@0 {
					reg = <0>;
					funnel_corinth_out_port: endpoint {
						remote-endpoint = <&funnel_soc_in_port>;
					};
				};

				port@1 {
					reg = <0>;
					funnel_corinth_from_lit_in_port: endpoint {
						slave-mode;
						remote-endpoint = <&corinth_etf_lit_out>;
					};
				};

				port@2 {
					reg = <1>;
					funnel_corinth_from_big_in_port: endpoint {
						slave-mode;
						remote-endpoint = <&corinth_etf_big_out>;
					};
				};
			};
		};

		/* corinth funnel big core0/1/2/6*/
		funnel@3e005000 {
			compatible = "arm,coresight-funnel", "arm,primecell";
			reg = <0 0x3e005000 0 0x1000>;
			clocks = <&ext_26m>;
			clock-names = "apb_pclk";

			ports {
				#address-cells = <1>;
				#size-cells = <0>;

				port@0 {
					reg = <0>;
					funnel_corinth_big_out_port: endpoint {
						remote-endpoint = <&corinth_etf_big_in>;
					};
				};

				port@1 {
					reg = <0>;
					funnel_core_in_port0: endpoint {
						slave-mode;
						remote-endpoint = <&etm0_out>;
					};
				};

				port@2 {
					reg = <1>;
					funnel_core_in_port1: endpoint {
						slave-mode;
						remote-endpoint = <&etm1_out>;
					};
				};

				port@3 {
					reg = <2>;
					funnel_core_in_port2: endpoint {
						slave-mode;
						remote-endpoint = <&etm2_out>;
					};
				};

				port@4 {
					reg = <3>;
					funnel_core_in_port6: endpoint {
						slave-mode;
						remote-endpoint = <&etm6_out>;
					};
				};

			};
		};

		etm@3f040000 {
			compatible = "arm,coresight-etm4x", "arm,primecell";
			reg = <0 0x3f040000 0 0x1000>;
			cpu = <&CPU0>;
			clocks = <&ext_26m>, <&aon_clk CLK_CSSYS>, <&pll2 CLK_TWPLL_512M>;
			clock-names = "apb_pclk", "clk_cs", "cs_src";

			port {
				etm0_out: endpoint {
					remote-endpoint = <&funnel_core_in_port0>;
				};
			};
		};

		etm@3f140000 {
			compatible = "arm,coresight-etm4x", "arm,primecell";
			reg = <0 0x3f140000 0 0x1000>;
			cpu = <&CPU1>;
			clocks = <&ext_26m>, <&aon_clk CLK_CSSYS>, <&pll2 CLK_TWPLL_512M>;
			clock-names = "apb_pclk", "clk_cs", "cs_src";

			port {
				etm1_out: endpoint {
					remote-endpoint = <&funnel_core_in_port1>;
				};
			};
		};

		etm@3f240000 {
			compatible = "arm,coresight-etm4x", "arm,primecell";
			reg = <0 0x3f240000 0 0x1000>;
			cpu = <&CPU2>;
			clocks = <&ext_26m>, <&aon_clk CLK_CSSYS>, <&pll2 CLK_TWPLL_512M>;
			clock-names = "apb_pclk", "clk_cs", "cs_src";

			port {
				etm2_out: endpoint {
					remote-endpoint = <&funnel_core_in_port2>;
				};
			};
		};

		etm@3f340000 {
			compatible = "arm,coresight-etm4x", "arm,primecell";
			reg = <0 0x3f340000 0 0x1000>;
			cpu = <&CPU3>;
			clocks = <&ext_26m>, <&aon_clk CLK_CSSYS>, <&pll2 CLK_TWPLL_512M>;
			clock-names = "apb_pclk", "clk_cs", "cs_src";

			port {
				etm3_out: endpoint {
					remote-endpoint = <&funnel_core_in_port3>;
				};
			};
		};

		etm@3f440000 {
			compatible = "arm,coresight-etm4x", "arm,primecell";
			reg = <0 0x3f440000 0 0x1000>;
			cpu = <&CPU4>;
			clocks = <&ext_26m>, <&aon_clk CLK_CSSYS>, <&pll2 CLK_TWPLL_512M>;
			clock-names = "apb_pclk", "clk_cs", "cs_src";

			port {
				etm4_out: endpoint {
					remote-endpoint = <&funnel_core_in_port4>;
				};
			};
		};

		etm@3f540000 {
			compatible = "arm,coresight-etm4x", "arm,primecell";
			reg = <0 0x3f540000 0 0x1000>;
			cpu = <&CPU5>;
			clocks = <&ext_26m>, <&aon_clk CLK_CSSYS>, <&pll2 CLK_TWPLL_512M>;
			clock-names = "apb_pclk", "clk_cs", "cs_src";

			port {
				etm5_out: endpoint {
					remote-endpoint = <&funnel_core_in_port5>;
				};
			};
		};

		etm@3f640000 {
			compatible = "arm,coresight-etm4x", "arm,primecell";
			reg = <0 0x3f640000 0 0x1000>;
			cpu = <&CPU6>;
			clocks = <&ext_26m>, <&aon_clk CLK_CSSYS>, <&pll2 CLK_TWPLL_512M>;
			clock-names = "apb_pclk", "clk_cs", "cs_src";

			port {
				etm6_out: endpoint {
					remote-endpoint = <&funnel_core_in_port6>;
				};
			};
		};

		etm@3f740000 {
			compatible = "arm,coresight-etm4x", "arm,primecell";
			reg = <0 0x3f740000 0 0x1000>;
			cpu = <&CPU7>;
			clocks = <&ext_26m>, <&aon_clk CLK_CSSYS>, <&pll2 CLK_TWPLL_512M>;
			clock-names = "apb_pclk", "clk_cs", "cs_src";

			port {
				etm7_out: endpoint {
					remote-endpoint = <&funnel_core_in_port7>;
				};
			};
		};
	};
};

&sdio0 {
	clock-names = "sdio_clk", "sdio_clk_source",
		      "sdio_ahb_enable", "sdio_hp_det_clk";
	clocks = <&ap_clk CLK_SDIO0_2X>,
		 <&pll1 CLK_RPLL>,
		 <&apapb_gate CLK_SDIO0_EB>,
		 <&apapb_gate CLK_SDIO0_32K_EB>;
};

&sdio1 {
	clock-names = "sdio_clk","sdio_clk_source","sdio_ahb_enable";
	clocks = <&ap_clk CLK_SDIO1_2X>,
		 <&pll2 CLK_LPLL_409M6>,
		 <&apapb_gate CLK_SDIO1_EB>;
};

&sdio3 {
	clock-names = "sdio_clk","sdio_clk_source","sdio_ahb_enable";
	clocks = <&ap_clk CLK_EMMC_2X>,
		 <&pll1 CLK_RPLL>,
		 <&apapb_gate CLK_EMMC_EB>;
};

&i2c0 {
	clock-names ="enable", "i2c", "source";
	clocks = <&apapb_gate CLK_I2C0_EB>,
		 <&ap_clk CLK_AP_I2C0>, <&ext_26m>;
};

&i2c1 {
	clock-names ="enable", "i2c", "source";
	clocks = <&apapb_gate CLK_I2C1_EB>,
		 <&ap_clk CLK_AP_I2C1>, <&ext_26m>;
};

&i2c2 {
	clock-names ="enable", "i2c", "source";
	clocks = <&apapb_gate CLK_I2C2_EB>,
		 <&ap_clk CLK_AP_I2C2>, <&ext_26m>;
};

&i2c3 {
	clock-names ="enable", "i2c", "source";
	clocks = <&apapb_gate CLK_I2C3_EB>,
		 <&ap_clk CLK_AP_I2C3>, <&ext_26m>;
};

&i2c4 {
	clock-names ="enable", "i2c", "source";
	clocks = <&apapb_gate CLK_I2C4_EB>,
		 <&ap_clk CLK_AP_I2C4>, <&ext_26m>;
};

&spi0 {
	clock-names = "enable", "spi", "source";
	clocks = <&apapb_gate CLK_SPI0_EB>,
		 <&ap_clk CLK_AP_SPI0>, <&pll2 CLK_TWPLL_192M>;
};

&spi1 {
	clock-names = "enable", "spi", "source";
	clocks = <&apapb_gate CLK_SPI1_EB>,
		 <&ap_clk CLK_AP_SPI1>, <&pll2 CLK_TWPLL_192M>;
};

&spi2 {
	clock-names = "enable", "spi", "source";
	clocks = <&apapb_gate CLK_SPI2_EB>,
		 <&ap_clk CLK_AP_SPI2>, <&pll2 CLK_TWPLL_192M>;
};

&spi3 {
	clock-names = "enable", "spi", "source";
	clocks = <&apapb_gate CLK_SPI3_EB>,
		 <&ap_clk CLK_AP_SPI3>, <&pll2 CLK_TWPLL_192M>;
};

&dpu {
	clock-names = "clk_src_96m",
			"clk_src_128m",
			"clk_src_153m6",
			"clk_src_192m",
			"clk_src_256m",
			"clk_src_307m2",
			"clk_src_384m",
			"clk_dpu_core",
			"clk_dpu_dpi",
			"clk_ap_ahb_disp_eb";

	clocks = <&pll2 CLK_TWPLL_96M>,
		<&pll2 CLK_TWPLL_128M>,
		<&pll2 CLK_TWPLL_153M6>,
		<&pll2 CLK_TWPLL_192M>,
		<&pll2 CLK_TWPLL_256M>,
		<&pll2 CLK_TWPLL_307M2>,
		<&pll2 CLK_TWPLL_384M>,
		<&ap_clk CLK_DISPC0>,
		<&ap_clk CLK_DISPC0_DPI>,
		<&apahb_gate CLK_DISPC_EB>;
};

&dsi {
	clock-names = "clk_ap_ahb_dsi_eb";
	clocks = <&apahb_gate CLK_DSI_EB>;
};

&gsp_core0 {
	clock-names =	"clk_dpu_core_src",
			"clk_dpu_core",
			"clk_ap_ahb_disp_eb";

	clocks =	<&pll2 CLK_TWPLL_384M>,
			<&ap_clk CLK_DISPC0>,
			<&apahb_gate CLK_DISPC_EB>;
};

&vsp {
	clock-names = "clk_ahb_gate_vsp_eb",
			"clk_src_256m",
			"clk_src_307m2",
			"clk_src_384m",
			"clk_vsp";
	clocks = <&apahb_gate CLK_VSP_EB>,
			<&pll2 CLK_TWPLL_256M>,
			<&pll2 CLK_TWPLL_307M2>,
			<&pll2 CLK_TWPLL_384M>,
			<&ap_clk CLK_VSP>;
};

&jpg {
	clock-names = "jpg_domain_eb",
			"jpg_dev_eb",
			"jpg_ckg_eb",
			"jpg_clk",
			"clk_src_76m8",
			"clk_src_128m",
			"clk_src_256m",
			"clk_src_384m";

	clocks = <&aonapb_gate CLK_MM_EB>,
			<&mm_gate CLK_MM_JPG_EB>,
			<&mm_gate CLK_MM_CKG_EB>,
			<&mm_clk CLK_JPG>,
			<&pll2 CLK_TWPLL_76M8>,
			<&pll2 CLK_TWPLL_128M>,
			<&pll2 CLK_TWPLL_256M>,
			<&pll2 CLK_TWPLL_384M>;
};

&gpu {
	clocks = <&aonapb_gate CLK_GPU_EB>,
		<&gpu_clk CLK_GPU_CORE_EB>,
		<&gpu_clk CLK_GPU_MEM_EB>,
		<&gpu_clk CLK_GPU_SYS_EB>,
		<&pll2 CLK_TWPLL_384M>,
		<&pll2 CLK_TWPLL_512M>,
		<&pll2 CLK_LPLL_614M4>,
		<&pll2 CLK_TWPLL_768M>,
		<&pll2 CLK_GPLL>;
};
